# STM32F303 register map
File version: 1.4
CPU: CM4 r1p0, little endian, no MPU, no FPU, 4 interrupt priority bits
Registers are 32-bit, read-write, reset 0x0 unless marked. A register's access mark holds for its fields unless they carry their own. Offsets are from the block's base; [hi:lo] are bit positions; {n}, {i} and the like mark numbered series; 'fields as' and 'values as' point back to an identical list.

## SYSCFG — System configuration controller
Base 0x40010000
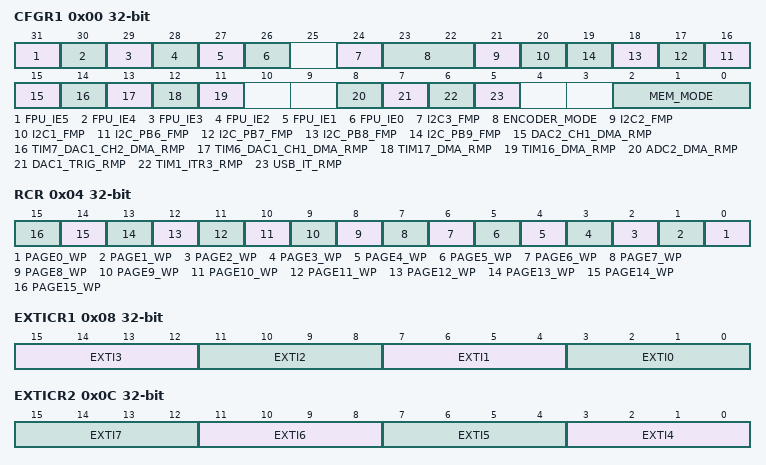
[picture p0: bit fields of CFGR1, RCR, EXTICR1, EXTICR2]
0x00 CFGR1 — configuration register 1
  [31] FPU_IE5 — Inexact interrupt enable
    0=Disabled (Inexact interrupt disable); 1=Enabled (Inexact interrupt enable)
  [30] FPU_IE4 — Input denormal interrupt enable
    0=Disabled (Input denormal interrupt disable); 1=Enabled (Input denormal interrupt enable)
  [29] FPU_IE3 — Overflow interrupt enable
    0=Disabled (Overflow interrupt disable); 1=Enabled (Overflow interrupt enable)
  [28] FPU_IE2 — Underflow interrupt enable
    0=Disabled (Underflow interrupt disable); 1=Enabled (Underflow interrupt enable)
  [27] FPU_IE1 — Devide-by-zero interrupt enable
    0=Disabled (Devide-by-zero interrupt disable); 1=Enabled (Devide-by-zero interrupt enable)
  [26] FPU_IE0 — Invalid operation interrupt enable
    0=Disabled (Invalid operation interrupt disable); 1=Enabled (Invalid operation interrupt enable)
  [24] I2C3_FMP — I2C3 Fast Mode Plus
    0=Standard (FM+ mode is controlled by I2C_Pxx_FMP bits only); 1=FMP (FM+ mode is enabled on all I2C3 pins selected through selection through IOPORT control registers AF selection bits)
  [23:22] ENCODER_MODE
    0=NoRedirection; 1=MapTim2Tim15 (TIM2 IC1 and TIM2 IC2 are connected to TIM15 IC1 and TIM15 IC2 respectively); 2=MapTim3Tim15 (TIM3 IC1 and TIM3 IC2 are connected to TIM15 IC1 and TIM15 IC2 respectively); 3=MapTim4Tim15 (TIM4 IC1 and TIM4 IC2 are connected to TIM15 IC1 and TIM15 IC2 respectively (STM32F303xB/C and STM32F358xC devices only))
  [21] I2C2_FMP — I2C2 Fast Mode Plus
    0=Standard (FM+ mode is controlled by I2C_Pxx_FMP bits only); 1=FMP (FM+ mode is enabled on all I2C2 pins selected through selection through IOPORT control registers AF selection bits)
  [20] I2C1_FMP — I2C1 Fast Mode Plus
    0=Standard (FM+ mode is controlled by I2C_Pxx_FMP bits only); 1=FMP (FM+ mode is enabled on all I2C1 pins selected through selection through IOPORT control registers AF selection bits)
  [n+10] I2C_PB{n}_FMP (n=6..9) — Fast Mode Plus (FM+) driving capability activation bits.
    0=Standard (PB{n} pin operate in standard mode); 1=FMP (I2C FM+ mode enabled on PB{n} and the Speed control is bypassed)
  [15] DAC2_CH1_DMA_RMP — DAC2 channel1 DMA remap
    0=NotRemapped; 1=Remapped (DAC2_CH1 DMA requests mapped on DMA1 channel 5)
  [14] TIM7_DAC1_CH2_DMA_RMP — TIM7 and DAC2 DMA request remapping bit
    0=NotRemapped (TIM7_UP and DAC_CH2 DMA requests mapped on DMA2 channel 4 in STM32F303xB/C and STM32F358xC devices); 1=Remapped (TIM7_UP and DAC_CH2 DMA requests mapped on DMA1 channel 4)
  [13] TIM6_DAC1_CH1_DMA_RMP — TIM6 and DAC1 DMA request remapping bit
    0=NotRemapped (TIM6_UP and DAC_CH1 DMA requests mapped on DMA2 channel 3 in STM32F303xB/C and STM32F358xC); 1=Remapped (TIM6_UP and DAC_CH1 DMA requests mapped on DMA1 channel 3)
  [12] TIM17_DMA_RMP — TIM17 DMA request remapping bit
    0=NotRemapped (TIM17_CH1 and TIM17_UP DMA requests mapped on DMA channel 1); 1=Remapped (TIM17_CH1 and TIM17_UP DMA requests mapped on DMA channel 2)
  [11] TIM16_DMA_RMP — TIM16 DMA request remapping bit
    0=NotRemapped (TIM16_CH1 and TIM16_UP DMA requests mapped on DMA channel 3); 1=Remapped (TIM16_CH1 and TIM16_UP DMA requests mapped on DMA channel 4)
  [8] ADC2_DMA_RMP — ADC24 DMA remapping bit
    0=NotRemapped (ADC24 DMA requests mapped on DMA2 channels 1 and 2); 1=Remapped (ADC24 DMA requests mapped on DMA2 channels 3 and 4)
  [7] DAC1_TRIG_RMP — DAC trigger remap (when TSEL = 001)
    0=NotRemapped (DAC trigger is TIM8_TRGO in STM32F303xB/C and STM32F358xC devices); 1=Remapped (DAC trigger is TIM3_TRGO)
  [6] TIM1_ITR3_RMP — Timer 1 ITR3 selection
    0=NotRemapped (TIM1_ITR3 = TIM4_TRGO in STM32F303xB/C and STM32F358xC devices); 1=Remapped (TIM1_ITR3 = TIM17_OC)
  [5] USB_IT_RMP — USB interrupt remap
    0=NotRemapped (USB_HP, USB_LP and USB_WAKEUP interrupts are mapped on interrupt lines 19, 20 and 42 respectively); 1=Remapped (USB_HP, USB_LP and USB_WAKEUP interrupts are mapped on interrupt lines 74, 75 and 76 respectively)
  [2:0] MEM_MODE — Memory mapping selection bits
    0=Main Flash memory mapped at 0x0000_0000; 1=System Flash memory mapped at 0x0000_0000; 3=SRAM (Embedded SRAM mapped at 0x0000_0000); 4=FMC (FMC Bank (Only the first two banks) (Available on STM32F303xD/E only))
0x04 RCR — CCM SRAM protection register
  [all] fields
    0=Disabled (Write protection of pagex is disabled); 1=Enabled (Write protection of pagex is enabled)
  [n] PAGE{n}_WP (n=0..15) — CCM SRAM page write protection bit
0x08 EXTICR1 — external interrupt configuration register 1
  [15:12] EXTI3 — EXTI 3 configuration bits
    0=PA3 (Select PA3 as the source input for the EXTI3 external interrupt); 1=PB3 (Select PB3 as the source input for the EXTI3 external interrupt); 2=PC3 (Select PC3 as the source input for the EXTI3 external interrupt); 3=PD3 (Select PD3 as the source input for the EXTI3 external interrupt); 4=PE3 (Select PE3 as the source input for the EXTI3 external interrupt); 5=PF3 (Select PF3 as the source input for the EXTI3 external interrupt); 6=PG3 (Select PG3 as the source input for the EXTI3 external interrupt)
  [11:8] EXTI2 — EXTI 2 configuration bits
    0=PA2 (Select PA2 as the source input for the EXTI2 external interrupt); 1=PB2 (Select PB2 as the source input for the EXTI2 external interrupt); 2=PC2 (Select PC2 as the source input for the EXTI2 external interrupt); 3=PD2 (Select PD2 as the source input for the EXTI2 external interrupt); 4=PE2 (Select PE2 as the source input for the EXTI2 external interrupt); 5=PF2 (Select PF2 as the source input for the EXTI2 external interrupt); 6=PG2 (Select PG2 as the source input for the EXTI2 external interrupt); 7=PH2 (Select PH2 as the source input for the EXTI2 external interrupt)
  [7:4] EXTI1 — EXTI 1 configuration bits
    0=PA1 (Select PA1 as the source input for the EXTI1 external interrupt); 1=PB1 (Select PB1 as the source input for the EXTI1 external interrupt); 2=PC1 (Select PC1 as the source input for the EXTI1 external interrupt); 3=PD1 (Select PD1 as the source input for the EXTI1 external interrupt); 4=PE1 (Select PE1 as the source input for the EXTI1 external interrupt); 5=PF1 (Select PF1 as the source input for the EXTI1 external interrupt); 6=PG1 (Select PG1 as the source input for the EXTI1 external interrupt); 7=PH1 (Select PH1 as the source input for the EXTI1 external interrupt)
  [3:0] EXTI0 — EXTI 0 configuration bits
    0=PA0 (Select PA0 as the source input for the EXTI0 external interrupt); 1=PB0 (Select PB0 as the source input for the EXTI0 external interrupt); 2=PC0 (Select PC0 as the source input for the EXTI0 external interrupt); 3=PD0 (Select PD0 as the source input for the EXTI0 external interrupt); 4=PE0 (Select PE0 as the source input for the EXTI0 external interrupt); 5=PF0 (Select PF0 as the source input for the EXTI0 external interrupt); 6=PG0 (Select PG0 as the source input for the EXTI0 external interrupt); 7=PH0 (Select PH0 as the source input for the EXTI0 external interrupt)
0x0C EXTICR2 — external interrupt configuration register 2
  [4n-13:4n-16] EXTI{n} (n=4..7) — EXTI {n} configuration bits
    0=PA{n} (Select PA{n} as the source input for the EXTI{n} external interrupt); 1=PB{n} (Select PB{n} as the source input for the EXTI{n} external interrupt); 2=PC{n} (Select PC{n} as the source input for the EXTI{n} external interrupt); 3=PD{n} (Select PD{n} as the source input for the EXTI{n} external interrupt); 4=PE{n} (Select PE{n} as the source input for the EXTI{n} external interrupt); 5=PF{n} (Select PF{n} as the source input for the EXTI{n} external interrupt); 6=PG{n} (Select PG{n} as the source input for the EXTI{n} external interrupt)
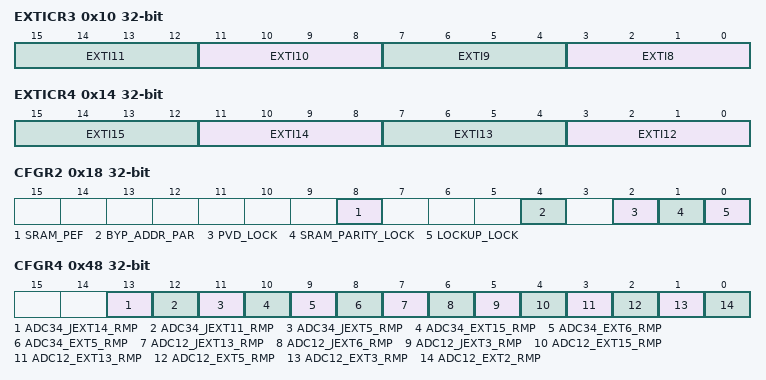
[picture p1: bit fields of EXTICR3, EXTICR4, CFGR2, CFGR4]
0x10 EXTICR3 — external interrupt configuration register 3
  [4n-29:4n-32] EXTI{n} (n=8..11) — EXTI {n} configuration bits
    values as EXTICR2.EXTI4
0x14 EXTICR4 — external interrupt configuration register 4
  [4n-45:4n-48] EXTI{n} (n=12..15) — EXTI {n} configuration bits
    values as EXTICR2.EXTI4
0x18 CFGR2 — configuration register 2
  [8] SRAM_PEF — SRAM parity flag
    on read: 0=NoParityError (No SRAM parity error detected); 1=ParityErrorDetected (SRAM parity error detected) | on write: 1=Clear SRAM parity error flag
  [4] BYP_ADDR_PAR — Bypass address bit 29 in parity calculation
    0=NoBypass (The ramload operation is performed taking into consideration bit 29 of the address when the parity is calculated); 1=Bypass (The ramload operation is performed without taking into consideration bit 29 of the address when the parity is calculated)
  [2] PVD_LOCK — PVD lock enable bit
    0=Disconnected (PVD interrupt disconnected from TIM15/16/17 Break input); 1=Connected (PVD interrupt connected to TIM15/16/17 Break input)
  [1] SRAM_PARITY_LOCK — SRAM parity lock bit
    0=Disconnected (SRAM parity error disconnected from TIM1/15/16/17 Break input); 1=Connected (SRAM parity error connected to TIM1/15/16/17 Break input)
  [0] LOCKUP_LOCK — Cortex-M0 LOCKUP bit enable bit
    0=Disconnected (Cortex-M4F LOCKUP output disconnected from TIM1/15/16/17 Break input); 1=Connected (Cortex-M4F LOCKUP output connected to TIM1/15/16/17 Break input)
0x48 CFGR4 — configuration register 4
  [13] ADC34_JEXT14_RMP — Controls the Input trigger of ADC34 injected channel JEXT14
    0=Tim7 (Trigger source is TIM7_TRGO); 1=Tim20 (Trigger source is TIM20_CC2)
  [12] ADC34_JEXT11_RMP — Controls the Input trigger of ADC34 injected channel JEXT11
    0=Tim1 (Trigger source is TIM1_CC3); 1=Tim20 (Trigger source is TIM20_TRGO2)
  [11] ADC34_JEXT5_RMP — Controls the Input trigger of ADC34 injected channel JEXT5
    0=Tim4 (Trigger source is TIM4_CC3); 1=Tim20 (Trigger source is TIM20_TRGO)
  [10] ADC34_EXT15_RMP — Controls the Input trigger of ADC34 regular channel EXT15
    0=Tim2 (Trigger source is TIM2_CC1); 1=Tim20 (Trigger source is TIM20_CC1)
  [9] ADC34_EXT6_RMP — Controls the Input trigger of ADC34 regular channel EXT6
    0=Tim4 (Trigger source is TIM4_CC1); 1=Tim20 (Trigger source is TIM20_TRGO2)
  [8] ADC34_EXT5_RMP — Controls the Input trigger of ADC34 regular channel EXT5
    0=Exti2 (Trigger source is EXTI line 2 when reset at 0); 1=Tim20 (Trigger source is TIM20_TRGO)
  [7] ADC12_JEXT13_RMP — Controls the Input trigger of ADC12 injected channel JEXT13
    0=Tim3 (Trigger source is TIM3_CC1); 1=Tim20 (Trigger source is TIM20_CC4)
  [6] ADC12_JEXT6_RMP — Controls the Input trigger of ADC12 injected channel JEXT6
    0=Exti15 (Trigger source is EXTI line 15); 1=Tim20 (Trigger source is TIM20_TRGO2)
  [5] ADC12_JEXT3_RMP — Controls the Input trigger of ADC12 injected channel JEXT3
    0=Tim2 (Trigger source is TIM2_CC1); 1=Tim20 (Trigger source is TIM20_TRGO)
  [4] ADC12_EXT15_RMP — Controls the Input trigger of ADC12 regular channel EXT15
    0=Tim3 (Trigger source is TIM3_CC4); 1=Tim20 (Trigger source is TIM20_CC3)
  [3] ADC12_EXT13_RMP — Controls the Input trigger of ADC12 regular channel EXT13
    0=Tim6 (Trigger source is TIM6_TRGO); 1=Tim20 (Trigger source is TIM20_CC2)
  [2] ADC12_EXT5_RMP — Controls the Input trigger of ADC12 regular channel EXT5
    0=Tim4 (Trigger source is TIM4_CC4); 1=Tim20 (Trigger source is TIM20_CC1)
  [1] ADC12_EXT3_RMP — Controls the Input trigger of ADC12 regular channel EXT3
    0=Tim2 (Trigger source is TIM2_CC2); 1=Tim20 (rigger source is TIM20_TRGO2)
  [0] ADC12_EXT2_RMP — Controls the Input trigger of ADC12 regular channel EXT2
    0=Tim1 (Trigger source is TIM3_CC3); 1=Tim20 (rigger source is TIM20_TRGO)
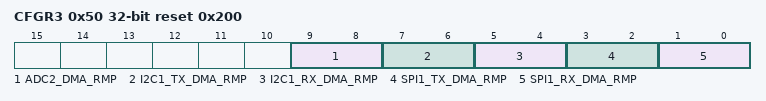
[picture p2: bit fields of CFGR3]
0x50 CFGR3 reset 0x200 — configuration register 3
  [9:8] ADC2_DMA_RMP — ADC2 DMA remapping bit
    0=MapDma2 (ADC2 mapped on DMA2); 2=MapDma1Ch2 (ADC2 mapped on DMA1 channel 2); 3=MapDma1Ch4 (ADC2 mapped on DMA1 channel 4)
  [7:6] I2C1_TX_DMA_RMP — I2C1_TX DMA remapping bit
    0=MapDma1Ch6 (I2C1_TX mapped on DMA1 CH6); 1=MapDma1Ch2 (I2C1_TX mapped on DMA1 CH2); 2=MapDma1Ch4 (I2C1_TX mapped on DMA1 CH4)
  [5:4] I2C1_RX_DMA_RMP — I2C1_RX DMA remapping bit
    0=MapDma1Ch7 (I2C1_RX mapped on DMA1 CH7); 1=MapDma1Ch3 (I2C1_RX mapped on DMA1 CH3); 2=MapDma1Ch5 (I2C1_RX mapped on DMA1 CH5)
  [3:2] SPI1_TX_DMA_RMP — SPI1_TX DMA remapping bit
    0=MapDma1Ch3 (SPI1_TX mapped on DMA1 CH3); 1=MapDma1Ch5 (SPI1_TX mapped on DMA1 CH5); 2=MapDma1Ch7 (SPI1_TX mapped on DMA1 CH7)
  [1:0] SPI1_RX_DMA_RMP — SPI1_RX DMA remapping bit
    0=MapDma1Ch3 (SPI1_RX mapped on DMA1 CH2); 1=MapDma1Ch5 (SPI1_RX mapped on DMA1 CH4); 2=MapDma1Ch7 (SPI1_RX mapped on DMA1 CH6)
